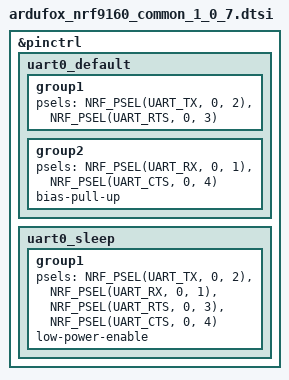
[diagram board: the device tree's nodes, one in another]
/*
 * Copyright (c) 2021 Nordic Semiconductor ASA
 *
 * SPDX-License-Identifier: Apache-2.0
 */


 &pinctrl {
	uart0_default: uart0_default {
		group1 {
			psels = <NRF_PSEL(UART_TX, 0, 2)>,
				<NRF_PSEL(UART_RTS, 0, 3)>;
		};
		group2 {
			psels = <NRF_PSEL(UART_RX, 0, 1)>,
				<NRF_PSEL(UART_CTS, 0, 4)>;
			bias-pull-up;
		};
	};

	uart0_sleep: uart0_sleep {
		group1 {
			psels = <NRF_PSEL(UART_TX, 0, 2)>,
				<NRF_PSEL(UART_RX, 0, 1)>,
				<NRF_PSEL(UART_RTS, 0, 3)>,
				<NRF_PSEL(UART_CTS, 0, 4)>;
			low-power-enable;
		};
	};
};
